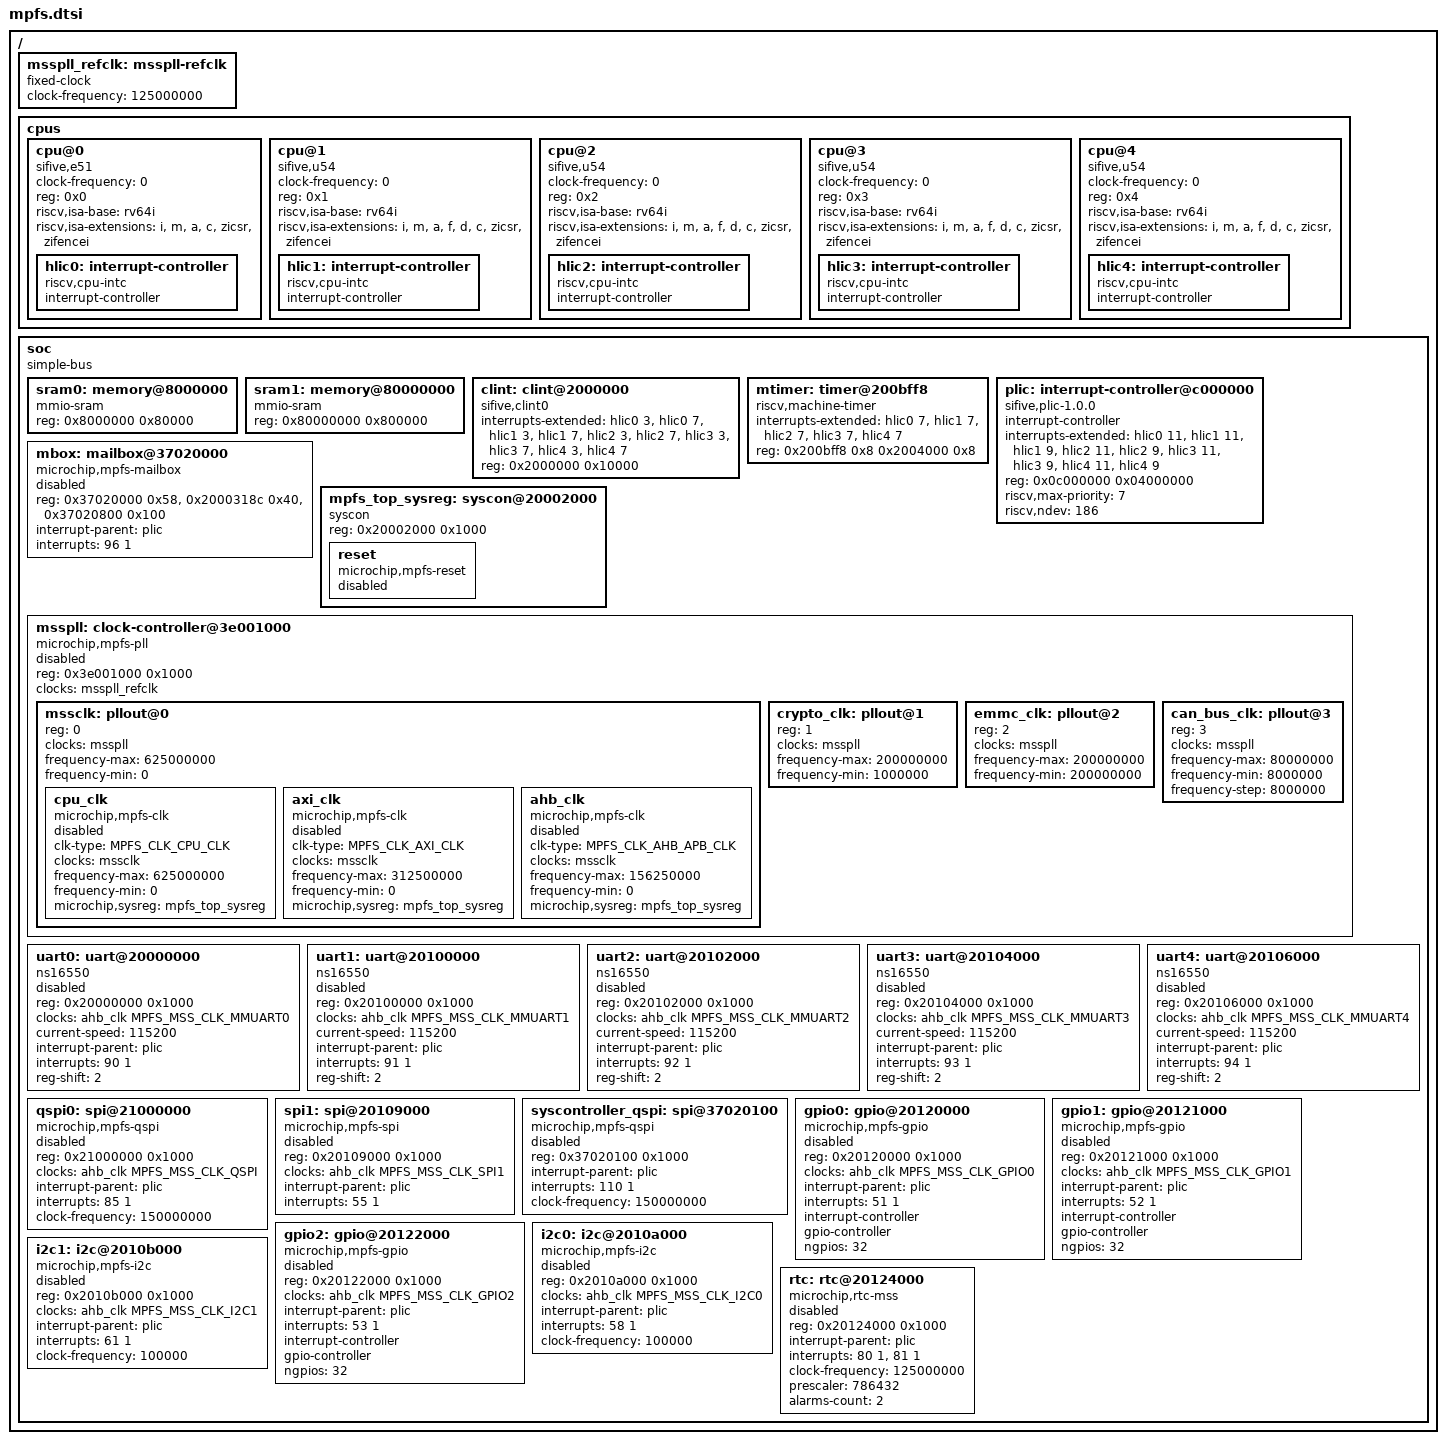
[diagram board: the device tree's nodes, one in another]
/*
 * Copyright (c) 2018 Linaro Limited
 *
 * SPDX-License-Identifier: Apache-2.0
 */

#include <skeleton.dtsi>
#include <zephyr/dt-bindings/gpio/gpio.h>
#include <zephyr/dt-bindings/reset/mchp_mss_reset.h>
#include <zephyr/dt-bindings/clock/mchp_mss_clock.h>

/ {
	#address-cells = <1>;
	#size-cells = <1>;

	msspll_refclk: msspll-refclk {
		compatible = "fixed-clock";
		#clock-cells = <0>;
		clock-frequency = <125000000>;
	};

	cpus {
		#address-cells = <1>;
		#size-cells = <0>;

		cpu@0 {
			clock-frequency = <0>;
			compatible = "sifive,e51", "riscv";
			device_type = "cpu";
			reg = <0x0>;
			riscv,isa-base = "rv64i";
			riscv,isa-extensions = "i", "m", "a", "c", "zicsr", "zifencei";

			hlic0: interrupt-controller {
				compatible = "riscv,cpu-intc";
				#address-cells = <0>;
				#interrupt-cells = <1>;
				interrupt-controller;
			};
		};

		cpu@1 {
			clock-frequency = <0>;
			compatible = "sifive,u54", "riscv";
			device_type = "cpu";
			reg = <0x1>;
			riscv,isa-base = "rv64i";
			riscv,isa-extensions = "i", "m", "a", "f", "d", "c", "zicsr", "zifencei";

			hlic1: interrupt-controller {
				compatible = "riscv,cpu-intc";
				#address-cells = <0>;
				#interrupt-cells = <1>;
				interrupt-controller;
			};
		};

		cpu@2 {
			clock-frequency = <0>;
			compatible = "sifive,u54", "riscv";
			device_type = "cpu";
			reg = <0x2>;
			riscv,isa-base = "rv64i";
			riscv,isa-extensions = "i", "m", "a", "f", "d", "c", "zicsr", "zifencei";

			hlic2: interrupt-controller {
				compatible = "riscv,cpu-intc";
				#address-cells = <0>;
				#interrupt-cells = <1>;
				interrupt-controller;
			};
		};

		cpu@3 {
			clock-frequency = <0>;
			compatible = "sifive,u54", "riscv";
			device_type = "cpu";
			reg = <0x3>;
			riscv,isa-base = "rv64i";
			riscv,isa-extensions = "i", "m", "a", "f", "d", "c", "zicsr", "zifencei";

			hlic3: interrupt-controller {
				compatible = "riscv,cpu-intc";
				#address-cells = <0>;
				#interrupt-cells = <1>;
				interrupt-controller;
			};
		};

		cpu@4 {
			clock-frequency = <0>;
			compatible = "sifive,u54", "riscv";
			device_type = "cpu";
			reg = <0x4>;
			riscv,isa-base = "rv64i";
			riscv,isa-extensions = "i", "m", "a", "f", "d", "c", "zicsr", "zifencei";

			hlic4: interrupt-controller {
				compatible = "riscv,cpu-intc";
				#address-cells = <0>;
				#interrupt-cells = <1>;
				interrupt-controller;
			};
		};
	};

	soc {
		#address-cells = <1>;
		#size-cells = <1>;
		compatible = "simple-bus";
		ranges;

		sram0: memory@8000000 {
			compatible = "mmio-sram";
			reg = <0x8000000 0x80000>;
		};

		sram1: memory@80000000 {
			compatible = "mmio-sram";
			reg = <0x80000000 0x800000>;
		};

		clint: clint@2000000 {
			compatible = "sifive,clint0";
			interrupts-extended = <&hlic0 3 &hlic0 7
					       &hlic1 3 &hlic1 7
					       &hlic2 3 &hlic2 7
					       &hlic3 3 &hlic3 7
					       &hlic4 3 &hlic4 7>;
			interrupt-names = "soft0", "timer0", "soft1", "timer1",
					  "soft2", "timer2", "soft3", "timer3",
					  "soft4", "timer4";
			reg = <0x2000000 0x10000>;
		};

		mtimer: timer@200bff8 {
			compatible = "riscv,machine-timer";
			interrupts-extended = <&hlic0 7
					       &hlic1 7
					       &hlic2 7
					       &hlic3 7
					       &hlic4 7>;
			reg = <0x200bff8 0x8 0x2004000 0x8>;
			reg-names = "mtime", "mtimecmp";
		};

		plic: interrupt-controller@c000000 {
			compatible = "sifive,plic-1.0.0";
			#interrupt-cells = <2>;
			#address-cells = <1>;
			interrupt-controller;
			interrupts-extended = <&hlic0 11
					       &hlic1 11 &hlic1 9
					       &hlic2 11 &hlic2 9
					       &hlic3 11 &hlic3 9
					       &hlic4 11 &hlic4 9>;
			reg = <0x0c000000 0x04000000>;
			riscv,max-priority = <7>;
			riscv,ndev = <186>;
		};

		mbox: mailbox@37020000 {
			compatible = "microchip,mpfs-mailbox";
			reg = <0x37020000 0x58>, <0x2000318c 0x40>,
			      <0x37020800 0x100>;
			interrupt-parent = <&plic>;
			interrupts = <96 1>;
			#mbox-cells = <1>;
			status = "disabled";
		};

		mpfs_top_sysreg: syscon@20002000 {
			compatible = "syscon";
			reg = <0x20002000 0x1000>;
			status = "okay";

			reset: reset {
				compatible = "microchip,mpfs-reset";
				#reset-cells = <1>;
				status = "disabled";
			};
		};

		msspll: clock-controller@3e001000 {
			compatible = "microchip,mpfs-pll";
			reg = <0x3e001000 0x1000>;
			clocks = <&msspll_refclk>;
			#clock-cells = <0>;
			#address-cells = <1>;
			#size-cells = <0>;
			status = "disabled";

			mssclk: pllout@0 {
				reg = <0>;
				clocks = <&msspll>;
				#clock-cells = <0>;
				frequency-max = <625000000>;
				frequency-min = <0>;

				cpu_clk: cpu_clk {
					compatible = "microchip,mpfs-clk";
					clk-type = <MPFS_CLK_CPU_CLK>;
					clocks = <&mssclk>;
					#clock-cells = <0>;
					frequency-max = <625000000>;
					frequency-min = <0>;
					microchip,sysreg = <&mpfs_top_sysreg>;
					status = "disabled";
				};

				axi_clk: axi_clk {
					compatible = "microchip,mpfs-clk";
					clk-type = <MPFS_CLK_AXI_CLK>;
					clocks = <&mssclk>;
					#clock-cells = <0>;
					frequency-max = <312500000>;
					frequency-min = <0>;
					microchip,sysreg = <&mpfs_top_sysreg>;
					status = "disabled";
				};

				ahb_clk: ahb_clk {
					compatible = "microchip,mpfs-clk";
					clk-type = <MPFS_CLK_AHB_APB_CLK>;
					clocks = <&mssclk>;
					#clock-cells = <1>;
					frequency-max = <156250000>;
					frequency-min = <0>;
					microchip,sysreg = <&mpfs_top_sysreg>;
					status = "disabled";
				};
			};

			crypto_clk: pllout@1 {
				reg = <1>;
				clocks = <&msspll>;
				#clock-cells = <0>;
				frequency-max = <200000000>;
				frequency-min = <1000000>;
			};

			emmc_clk: pllout@2 {
				reg = <2>;
				clocks = <&msspll>;
				#clock-cells = <0>;
				frequency-max = <200000000>;
				frequency-min = <200000000>;
			};

			can_bus_clk: pllout@3 {
				reg = <3>;
				clocks = <&msspll>;
				#clock-cells = <0>;
				frequency-max = <80000000>;
				frequency-min = <8000000>;
				frequency-step = <8000000>;
			};
		};

		uart0: uart@20000000 {
			compatible = "ns16550";
			reg = <0x20000000 0x1000>;
			clocks = <&ahb_clk MPFS_MSS_CLK_MMUART0>;
			current-speed = <115200>;
			interrupt-parent = <&plic>;
			interrupts = <90 1>;
			reg-shift = <2>;
			status = "disabled";
		};

		uart1: uart@20100000 {
			compatible = "ns16550";
			reg = <0x20100000 0x1000>;
			clocks = <&ahb_clk MPFS_MSS_CLK_MMUART1>;
			current-speed = <115200>;
			interrupt-parent = <&plic>;
			interrupts = <91 1>;
			reg-shift = <2>;
			status = "disabled";
		};

		uart2: uart@20102000 {
			compatible = "ns16550";
			reg = <0x20102000 0x1000>;
			clocks = <&ahb_clk MPFS_MSS_CLK_MMUART2>;
			current-speed = <115200>;
			interrupt-parent = <&plic>;
			interrupts = <92 1>;
			reg-shift = <2>;
			status = "disabled";
		};

		uart3: uart@20104000 {
			compatible = "ns16550";
			reg = <0x20104000 0x1000>;
			clocks = <&ahb_clk MPFS_MSS_CLK_MMUART3>;
			current-speed = <115200>;
			interrupt-parent = <&plic>;
			interrupts = <93 1>;
			reg-shift = <2>;
			status = "disabled";
		};

		uart4: uart@20106000 {
			compatible = "ns16550";
			reg = <0x20106000 0x1000>;
			clocks = <&ahb_clk MPFS_MSS_CLK_MMUART4>;
			current-speed = <115200>;
			interrupt-parent = <&plic>;
			interrupts = <94 1>;
			reg-shift = <2>;
			status = "disabled";
		};

		qspi0: spi@21000000 {
			compatible = "microchip,mpfs-qspi";
			#address-cells = <1>;
			#size-cells = <0>;
			reg = <0x21000000 0x1000>;
			clocks = <&ahb_clk MPFS_MSS_CLK_QSPI>;
			interrupt-parent = <&plic>;
			interrupts = <85 1>;
			status = "disabled";
			clock-frequency = <150000000>;
		};

		spi1: spi@20109000 {
			compatible = "microchip,mpfs-spi";
			#address-cells = <1>;
			#size-cells = <0>;
			reg = <0x20109000 0x1000>;
			clocks = <&ahb_clk MPFS_MSS_CLK_SPI1>;
			interrupt-parent = <&plic>;
			interrupts = <55 1>;
			status = "disabled";
		};

		syscontroller_qspi: spi@37020100 {
			compatible = "microchip,mpfs-qspi";
			#address-cells = <1>;
			#size-cells = <0>;
			reg = <0x37020100 0x1000>;
			interrupt-parent = <&plic>;
			interrupts = <110 1>;
			status = "disabled";
			clock-frequency = <150000000>;
		};

		gpio0: gpio@20120000 {
			compatible = "microchip,mpfs-gpio";
			reg = <0x20120000 0x1000>;
			clocks = <&ahb_clk MPFS_MSS_CLK_GPIO0>;
			interrupt-parent = <&plic>;
			interrupts = <51 1>;
			interrupt-controller;
			#interrupt-cells = <1>;
			gpio-controller;
			#gpio-cells = <2>;
			ngpios = <32>;
			status = "disabled";
		};

		gpio1: gpio@20121000 {
			compatible = "microchip,mpfs-gpio";
			reg = <0x20121000 0x1000>;
			clocks = <&ahb_clk MPFS_MSS_CLK_GPIO1>;
			interrupt-parent = <&plic>;
			interrupts = <52 1>;
			interrupt-controller;
			#interrupt-cells = <1>;
			gpio-controller;
			#gpio-cells = <2>;
			ngpios = <32>;
			status = "disabled";
		};

		gpio2: gpio@20122000 {
			compatible = "microchip,mpfs-gpio";
			reg = <0x20122000 0x1000>;
			clocks = <&ahb_clk MPFS_MSS_CLK_GPIO2>;
			interrupt-parent = <&plic>;
			interrupts = <53 1>;
			interrupt-controller;
			#interrupt-cells = <1>;
			gpio-controller;
			#gpio-cells = <2>;
			ngpios = <32>;
			status = "disabled";
		};

		i2c0: i2c@2010a000 {
			compatible = "microchip,mpfs-i2c";
			reg = <0x2010a000 0x1000>;
			clocks = <&ahb_clk MPFS_MSS_CLK_I2C0>;
			interrupt-parent = <&plic>;
			interrupts = <58 1>;
			#address-cells = <1>;
			#size-cells = <0>;
			clock-frequency = <100000>;
			status = "disabled";
		};

		i2c1: i2c@2010b000 {
			compatible = "microchip,mpfs-i2c";
			reg = <0x2010b000 0x1000>;
			clocks = <&ahb_clk MPFS_MSS_CLK_I2C1>;
			interrupt-parent = <&plic>;
			interrupts = <61 1>;
			#address-cells = <1>;
			#size-cells = <0>;
			clock-frequency = <100000>;
			status = "disabled";
		};

		rtc: rtc@20124000 {
			compatible = "microchip,rtc-mss";
			reg = <0x20124000 0x1000>;
			interrupt-parent = <&plic>;
			interrupts = <80 1>, <81 1>;
			clock-frequency = <125000000>;
			prescaler = <786432>;
			alarms-count = <2>;
			status = "disabled";
		};
	};
};
